AUTOSAR XML (schema 00044)
package /E40_Platform_System_SystemPackage/Components
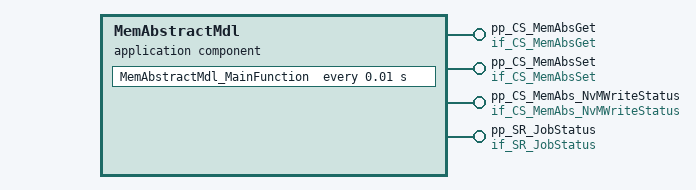
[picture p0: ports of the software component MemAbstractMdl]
  application sw component type MemAbstractMdl
    4 x provide port:
      pp_CS_MemAbsGet: provided-interface=if_CS_MemAbsGet
        provided-com-specs:
          operation=Get_BsConst_Audio_Element, queue-length=1
          operation=Get_BsConst_Communication_Element, queue-length=1
          operation=Get_BsConst_EngOffTimer_Element, queue-length=1
          operation=Get_BsConst_FuelGauge_Element, queue-length=1
          operation=Get_BsConst_Illumination_Element, queue-length=1
          operation=Get_BsConst_OilGauge_Element, queue-length=1
          operation=Get_BsConst_PowerGauge_Element, queue-length=1
          operation=Get_BsConst_Power_Element, queue-length=1
          operation=Get_BsConst_RealTimeClock_Element, queue-length=1
          operation=Get_BsConst_ServiceReminder_Element, queue-length=1
          operation=Get_BsConst_SpeedoGauge_Element, queue-length=1
          operation=Get_BsConst_TachoGauge_Element, queue-length=1
          operation=Get_BsConst_TempGauge_Element, queue-length=1
          operation=Get_BsConst_TripComputer_Element, queue-length=1
          operation=Get_BsConst_Warning_Element, queue-length=1
          operation=Get_BsCys_Certicificate_Element, queue-length=1
          operation=Get_BsDiag_Dtc_Element, queue-length=1
          operation=Get_BsDiag_ErrorRecord_Element, queue-length=1
          operation=Get_BsFuSa_Audio_Element, queue-length=1
          operation=Get_BsFuSa_Communication_Element, queue-length=1
          operation=Get_BsFuSa_Config_Element, queue-length=1
          operation=Get_BsFuSa_Display_Element, queue-length=1
          operation=Get_BsFuSa_Power_Element, queue-length=1
          operation=Get_BsFuSa_Warning_Element, queue-length=1
          operation=Get_BsFusa_Fota_Element, queue-length=1
          operation=Get_BsReten_Audio_Element, queue-length=1
          operation=Get_BsReten_Communication_Element, queue-length=1
          operation=Get_BsReten_Display_Element, queue-length=1
          operation=Get_BsReten_Gauges_Element, queue-length=1
          operation=Get_BsReten_Illumination_Element, queue-length=1
          operation=Get_BsReten_Odometer_Element, queue-length=1
          operation=Get_BsReten_Personalization_Element, queue-length=1
          operation=Get_BsReten_Power_Element, queue-length=1
          operation=Get_BsReten_RealTimeClock_Element, queue-length=1
          operation=Get_BsReten_Tripcomputer_Element, queue-length=1
          operation=Get_BsReten_VisDlt_Element, queue-length=1
          operation=Get_BsReten_Warning_Element, queue-length=1
          operation=Get_BsRt_CusDlt_Element, queue-length=1
          operation=Get_BsRt_FuelGauge_Element, queue-length=1
          operation=Get_BsRt_Illumination_Element, queue-length=1
          operation=Get_BsRt_Odometer_Element, queue-length=1
          operation=Get_BsRt_OilGauge_Element, queue-length=1
          operation=Get_BsRt_Personalization_Element, queue-length=1
          operation=Get_BsRt_PowerGauge_Element, queue-length=1
          operation=Get_BsRt_RealTimeClock_Element, queue-length=1
          operation=Get_BsRt_SpeedoGauge_Element, queue-length=1
          operation=Get_BsRt_TachoGauge_Element, queue-length=1
          operation=Get_BsRt_TempGauge_Element, queue-length=1
          operation=Get_BsRt_TripComputer_Element, queue-length=1
          operation=Get_BsRt_Warning_Element, queue-length=1
          operation=Get_BsShare_EcuPartNumber_Element, queue-length=1
          operation=Get_BsShare_SwUpdFotaFinPrint_Element, queue-length=1
          operation=Get_BsShare_SwUpdFotaMode_Element, queue-length=1
          operation=Get_BsShare_SwUpdFotaStatus_Element, queue-length=1
          operation=Get_BsShare_SwUpdFotadecrypt_Element, queue-length=1
          operation=Get_BsShare_SwUpdReflash_Element, queue-length=1
          operation=Get_BsShare_VehicleConfig_Element, queue-length=1
          operation=Get_BsShare_VisMeet_Element, queue-length=1
          operation=Get_RefCys_Certicificate1_Element, queue-length=1
          operation=Get_RefCys_Certicificate_Element, queue-length=1
      pp_CS_MemAbsSet: provided-interface=if_CS_MemAbsSet
        provided-com-specs:
          operation=Set_BsConst_Audio_Element, queue-length=1
          operation=Set_BsConst_Communication_Element, queue-length=1
          operation=Set_BsConst_EngOffTimer_Element, queue-length=1
          operation=Set_BsConst_FuelGauge_Element, queue-length=1
          operation=Set_BsConst_Illumination_Element, queue-length=1
          operation=Set_BsConst_OilGauge_Element, queue-length=1
          operation=Set_BsConst_PowerGauge_Element, queue-length=1
          operation=Set_BsConst_Power_Element, queue-length=1
          operation=Set_BsConst_RealTimeClock_Element, queue-length=1
          operation=Set_BsConst_ServiceReminder_Element, queue-length=1
          operation=Set_BsConst_SpeedoGauge_Element, queue-length=1
          operation=Set_BsConst_TachoGauge_Element, queue-length=1
          operation=Set_BsConst_TempGauge_Element, queue-length=1
          operation=Set_BsConst_TripComputer_Element, queue-length=1
          operation=Set_BsConst_Warning_Element, queue-length=1
          operation=Set_BsCys_Certicificate_Element, queue-length=1
          operation=Set_BsDiag_Dtc_Element, queue-length=1
          operation=Set_BsDiag_ErrorRecord_Element, queue-length=1
          operation=Set_BsFuSa_Audio_Element, queue-length=1
          operation=Set_BsFuSa_Communication_Element, queue-length=1
          operation=Set_BsFuSa_Config_Element, queue-length=1
          operation=Set_BsFuSa_Display_Element, queue-length=1
          operation=Set_BsFuSa_Power_Element, queue-length=1
          operation=Set_BsFuSa_Warning_Element, queue-length=1
          operation=Set_BsFusa_Fota_Element, queue-length=1
          operation=Set_BsReten_Audio_Element, queue-length=1
          operation=Set_BsReten_Communication_Element, queue-length=1
          operation=Set_BsReten_Display_Element, queue-length=1
          operation=Set_BsReten_Gauges_Element, queue-length=1
          operation=Set_BsReten_Illumination_Element, queue-length=1
          operation=Set_BsReten_Odometer_Element, queue-length=1
          operation=Set_BsReten_Personalization_Element, queue-length=1
          operation=Set_BsReten_Power_Element, queue-length=1
          operation=Set_BsReten_RealTimeClock_Element, queue-length=1
          operation=Set_BsReten_Tripcomputer_Element, queue-length=1
          operation=Set_BsReten_VisDlt_Element, queue-length=1
          operation=Set_BsReten_Warning_Element, queue-length=1
          operation=Set_BsRt_CusDlt_Element, queue-length=1
          operation=Set_BsRt_FuelGauge_Element, queue-length=1
          operation=Set_BsRt_Illumination_Element, queue-length=1
          operation=Set_BsRt_Odometer_Element, queue-length=1
          operation=Set_BsRt_OilGauge_Element, queue-length=1
          operation=Set_BsRt_Personalization_Element, queue-length=1
          operation=Set_BsRt_PowerGauge_Element, queue-length=1
          operation=Set_BsRt_RealTimeClock_Element, queue-length=1
          operation=Set_BsRt_SpeedoGauge_Element, queue-length=1
          operation=Set_BsRt_TachoGauge_Element, queue-length=1
          operation=Set_BsRt_TempGauge_Element, queue-length=1
          operation=Set_BsRt_TripComputer_Element, queue-length=1
          operation=Set_BsRt_Warning_Element, queue-length=1
          operation=Set_BsShare_EcuPartNumber_Element, queue-length=1
          operation=Set_BsShare_SwUpdFotaFinPrint_Element, queue-length=1
          operation=Set_BsShare_SwUpdFotaMode_Element, queue-length=1
          operation=Set_BsShare_SwUpdFotaStatus_Element, queue-length=1
          operation=Set_BsShare_SwUpdFotadecrypt_Element, queue-length=1
          operation=Set_BsShare_SwUpdReflash_Element, queue-length=1
          operation=Set_BsShare_VehicleConfig_Element, queue-length=1
          operation=Set_BsShare_VisMeet_Element, queue-length=1
          operation=Set_RefCys_Certicificate1_Element, queue-length=1
          operation=Set_RefCys_Certicificate_Element, queue-length=1
      pp_CS_MemAbs_NvMWriteStatus: server-com-spec{operation=NvmWriteStatus, queue-length=1}, provided-interface=if_CS_MemAbs_NvMWriteStatus
      pp_SR_JobStatus: provided-interface=if_SR_JobStatus
        provided-com-specs:
          data-element=JobStatus_BsConst_Audio_Element, init-value=constant-reference=MemAbstractMdlJobStatus_BsConst_Audio_ElementValue0
          data-element=JobStatus_BsConst_Communication_Element, init-value=constant-reference=MemAbstractMdlJobStatus_BsConst_Communication_ElementValue0
          data-element=JobStatus_BsConst_EngOffTimer_Element, init-value=constant-reference=MemAbstractMdlJobStatus_BsConst_EngOffTimer_ElementValue0
          data-element=JobStatus_BsConst_FuelGauge_Element, init-value=constant-reference=MemAbstractMdlJobStatus_BsConst_FuelGauge_ElementValue0
          data-element=JobStatus_BsConst_Illumination_Element, init-value=constant-reference=MemAbstractMdlJobStatus_BsConst_Illumination_ElementValue0
          data-element=JobStatus_BsConst_OilGauge_Element, init-value=constant-reference=MemAbstractMdlJobStatus_BsConst_OilGauge_ElementValue0
          data-element=JobStatus_BsConst_PowerGauge_Element, init-value=constant-reference=MemAbstractMdlJobStatus_BsConst_PowerGauge_ElementValue0
          data-element=JobStatus_BsConst_Power_Element, init-value=constant-reference=MemAbstractMdlJobStatus_BsConst_Power_ElementValue0
          data-element=JobStatus_BsConst_RealTimeClock_Element, init-value=constant-reference=MemAbstractMdlJobStatus_BsConst_RealTimeClock_ElementValue0
          data-element=JobStatus_BsConst_ServiceReminder_Element, init-value=constant-reference=MemAbstractMdlJobStatus_BsConst_ServiceReminder_ElementValue0
          data-element=JobStatus_BsConst_SpeedoGauge_Element, init-value=constant-reference=MemAbstractMdlJobStatus_BsConst_SpeedoGauge_ElementValue0
          data-element=JobStatus_BsConst_TachoGauge_Element, init-value=constant-reference=MemAbstractMdlJobStatus_BsConst_TachoGauge_ElementValue0
          data-element=JobStatus_BsConst_TempGauge_Element, init-value=constant-reference=MemAbstractMdlJobStatus_BsConst_TempGauge_ElementValue0
          data-element=JobStatus_BsConst_TripComputer_Element, init-value=constant-reference=MemAbstractMdlJobStatus_BsConst_TripComputer_ElementValue0
          data-element=JobStatus_BsConst_Warning_Element, init-value=constant-reference=MemAbstractMdlJobStatus_BsConst_Warning_ElementValue0
          data-element=JobStatus_BsCys_Certicificate_Element, init-value=constant-reference=MemAbstractMdlJobStatus_BsCys_Certicificate_ElementValue0
          data-element=JobStatus_BsDiag_Dtc_Element, init-value=constant-reference=MemAbstractMdlJobStatus_BsDiag_Dtc_ElementValue0
          data-element=JobStatus_BsDiag_ErrorRecord_Element, init-value=constant-reference=MemAbstractMdlJobStatus_BsDiag_ErrorRecord_ElementValue0
          data-element=JobStatus_BsFuSa_Audio_Element, init-value=constant-reference=MemAbstractMdlJobStatus_BsFuSa_Audio_ElementValue0
          data-element=JobStatus_BsFuSa_Communication_Element, init-value=constant-reference=MemAbstractMdlJobStatus_BsFuSa_Communication_ElementValue0
          data-element=JobStatus_BsFuSa_Config_Element, init-value=constant-reference=MemAbstractMdlJobStatus_BsFuSa_Config_ElementValue0
          data-element=JobStatus_BsFuSa_Display_Element, init-value=constant-reference=MemAbstractMdlJobStatus_BsFuSa_Display_ElementValue0
          data-element=JobStatus_BsFuSa_Power_Element, init-value=constant-reference=MemAbstractMdlJobStatus_BsFuSa_Power_ElementValue0
          data-element=JobStatus_BsFuSa_Warning_Element, init-value=constant-reference=MemAbstractMdlJobStatus_BsFuSa_Warning_ElementValue0
          data-element=JobStatus_BsFusa_Fota_Element, init-value=constant-reference=MemAbstractMdlJobStatus_BsFusa_Fota_ElementValue0
          data-element=JobStatus_BsReten_Audio_Element, init-value=constant-reference=MemAbstractMdlJobStatus_BsReten_Audio_ElementValue0
          data-element=JobStatus_BsReten_Communication_Element, init-value=constant-reference=MemAbstractMdlJobStatus_BsReten_Communication_ElementValue0
          data-element=JobStatus_BsReten_Display_Element, init-value=constant-reference=MemAbstractMdlJobStatus_BsReten_Display_ElementValue0
          data-element=JobStatus_BsReten_Gauges_Element, init-value=constant-reference=MemAbstractMdlJobStatus_BsReten_Gauges_ElementValue0
          data-element=JobStatus_BsReten_Illumination_Element, init-value=constant-reference=MemAbstractMdlJobStatus_BsReten_Illumination_ElementValue0
          data-element=JobStatus_BsReten_Odometer_Element, init-value=constant-reference=MemAbstractMdlJobStatus_BsReten_Odometer_ElementValue0
          data-element=JobStatus_BsReten_Personalization_Element, init-value=constant-reference=MemAbstractMdlJobStatus_BsReten_Personalization_ElementValue0
          data-element=JobStatus_BsReten_Power_Element, init-value=constant-reference=MemAbstractMdlJobStatus_BsReten_Power_ElementValue0
          data-element=JobStatus_BsReten_RealTimeClock_Element, init-value=constant-reference=MemAbstractMdlJobStatus_BsReten_RealTimeClock_ElementValue0
          data-element=JobStatus_BsReten_Tripcomputer_Element, init-value=constant-reference=MemAbstractMdlJobStatus_BsReten_Tripcomputer_ElementValue0
          data-element=JobStatus_BsReten_VisDlt_Element, init-value=constant-reference=MemAbstractMdlJobStatus_BsReten_VisDlt_ElementValue0
          data-element=JobStatus_BsReten_Warning_Element, init-value=constant-reference=MemAbstractMdlJobStatus_BsReten_Warning_ElementValue0
          data-element=JobStatus_BsRt_CusDlt_Element, init-value=constant-reference=MemAbstractMdlJobStatus_BsRt_CusDlt_ElementValue0
          data-element=JobStatus_BsRt_FuelGauge_Element, init-value=constant-reference=MemAbstractMdlJobStatus_BsRt_FuelGauge_ElementValue0
          data-element=JobStatus_BsRt_Illumination_Element, init-value=constant-reference=MemAbstractMdlJobStatus_BsRt_Illumination_ElementValue0
          data-element=JobStatus_BsRt_Odometer_Element, init-value=constant-reference=MemAbstractMdlJobStatus_BsRt_Odometer_ElementValue0
          data-element=JobStatus_BsRt_OilGauge_Element, init-value=constant-reference=MemAbstractMdlJobStatus_BsRt_OilGauge_ElementValue0
          data-element=JobStatus_BsRt_Personalization_Element, init-value=constant-reference=MemAbstractMdlJobStatus_BsRt_Personalization_ElementValue0
          data-element=JobStatus_BsRt_PowerGauge_Element, init-value=constant-reference=MemAbstractMdlJobStatus_BsRt_PowerGauge_ElementValue0
          data-element=JobStatus_BsRt_RealTimeClock_Element, init-value=constant-reference=MemAbstractMdlJobStatus_BsRt_RealTimeClock_ElementValue0
          data-element=JobStatus_BsRt_SpeedoGauge_Element, init-value=constant-reference=MemAbstractMdlJobStatus_BsRt_SpeedoGauge_ElementValue0
          data-element=JobStatus_BsRt_TachoGauge_Element, init-value=constant-reference=MemAbstractMdlJobStatus_BsRt_TachoGauge_ElementValue0
          data-element=JobStatus_BsRt_TempGauge_Element, init-value=constant-reference=MemAbstractMdlJobStatus_BsRt_TempGauge_ElementValue0
          data-element=JobStatus_BsRt_TripComputer_Element, init-value=constant-reference=MemAbstractMdlJobStatus_BsRt_TripComputer_ElementValue0
          data-element=JobStatus_BsRt_Warning_Element, init-value=constant-reference=MemAbstractMdlJobStatus_BsRt_Warning_ElementValue0
          data-element=JobStatus_BsShare_EcuPartNumber_Element, init-value=constant-reference=MemAbstractMdlJobStatus_BsShare_EcuPartNumber_ElementValue0
          data-element=JobStatus_BsShare_SwUpdFotaFinPrint_Element, init-value=constant-reference=MemAbstractMdlJobStatus_BsShare_SwUpdFotaFinPrint_ElementValue0
          data-element=JobStatus_BsShare_SwUpdFotaMode_Element, init-value=constant-reference=MemAbstractMdlJobStatus_BsShare_SwUpdFotaMode_ElementValue0
          data-element=JobStatus_BsShare_SwUpdFotaStatus_Element, init-value=constant-reference=MemAbstractMdlJobStatus_BsShare_SwUpdFotaStatus_ElementValue0
          data-element=JobStatus_BsShare_SwUpdFotadecrypt_Element, init-value=constant-reference=MemAbstractMdlJobStatus_BsShare_SwUpdFotadecrypt_ElementValue0
          data-element=JobStatus_BsShare_SwUpdReflash_Element, init-value=constant-reference=MemAbstractMdlJobStatus_BsShare_SwUpdReflash_ElementValue0
          data-element=JobStatus_BsShare_VehicleConfig_Element, init-value=constant-reference=MemAbstractMdlJobStatus_BsShare_VehicleConfig_ElementValue0
          data-element=JobStatus_BsShare_VisMeet_Element, init-value=constant-reference=MemAbstractMdlJobStatus_BsShare_VisMeet_ElementValue0
          data-element=JobStatus_RefCys_Certicificate1_Element, init-value=constant-reference=MemAbstractMdlJobStatus_RefCys_Certicificate1_ElementValue0
          data-element=JobStatus_RefCys_Certicificate_Element, init-value=constant-reference=MemAbstractMdlJobStatus_RefCys_Certicificate_ElementValue0
    behavior IB_MemAbstractMdl
      121 x operation invoked event:
        OIE_pp_CS_MemAbs_NvMWriteStatus_MemAbstractMdl_NvmWriteStatusTrigByNvmWriteStatus: start-on-event=MemAbstractMdl_NvmWriteStatus, operation=pp_CS_MemAbs_NvMWriteStatus.NvmWriteStatus
        OIE_pp_CS_MemAbsGet_MemAbstractMdl_Get_BsConst_Audio_ElementTrigByGet_BsConst_Audio_Element: start-on-event=MemAbstractMdl_Get_BsConst_Audio_Element, operation=pp_CS_MemAbsGet.Get_BsConst_Audio_Element
        OIE_pp_CS_MemAbsGet_MemAbstractMdl_Get_BsConst_Communication_ElementTrigByGet_BsConst_Communication_Element: start-on-event=MemAbstractMdl_Get_BsConst_Communication_Element, operation=pp_CS_MemAbsGet.Get_BsConst_Communication_Element
        OIE_pp_CS_MemAbsGet_MemAbstractMdl_Get_BsConst_EngOffTimer_ElementTrigByGet_BsConst_EngOffTimer_Element: start-on-event=MemAbstractMdl_Get_BsConst_EngOffTimer_Element, operation=pp_CS_MemAbsGet.Get_BsConst_EngOffTimer_Element
        OIE_pp_CS_MemAbsGet_MemAbstractMdl_Get_BsConst_FuelGauge_ElementTrigByGet_BsConst_FuelGauge_Element: start-on-event=MemAbstractMdl_Get_BsConst_FuelGauge_Element, operation=pp_CS_MemAbsGet.Get_BsConst_FuelGauge_Element
        OIE_pp_CS_MemAbsGet_MemAbstractMdl_Get_BsConst_Illumination_ElementTrigByGet_BsConst_Illumination_Element: start-on-event=MemAbstractMdl_Get_BsConst_Illumination_Element, operation=pp_CS_MemAbsGet.Get_BsConst_Illumination_Element
        OIE_pp_CS_MemAbsGet_MemAbstractMdl_Get_BsConst_OilGauge_ElementTrigByGet_BsConst_OilGauge_Element: start-on-event=MemAbstractMdl_Get_BsConst_OilGauge_Element, operation=pp_CS_MemAbsGet.Get_BsConst_OilGauge_Element
        OIE_pp_CS_MemAbsGet_MemAbstractMdl_Get_BsConst_PowerGauge_ElementTrigByGet_BsConst_PowerGauge_Element: start-on-event=MemAbstractMdl_Get_BsConst_PowerGauge_Element, operation=pp_CS_MemAbsGet.Get_BsConst_PowerGauge_Element
        OIE_pp_CS_MemAbsGet_MemAbstractMdl_Get_BsConst_Power_ElementTrigByGet_BsConst_Power_Element: start-on-event=MemAbstractMdl_Get_BsConst_Power_Element, operation=pp_CS_MemAbsGet.Get_BsConst_Power_Element
        OIE_pp_CS_MemAbsGet_MemAbstractMdl_Get_BsConst_RealTimeClock_ElementTrigByGet_BsConst_RealTimeClock_Element: start-on-event=MemAbstractMdl_Get_BsConst_RealTimeClock_Element, operation=pp_CS_MemAbsGet.Get_BsConst_RealTimeClock_Element
        OIE_pp_CS_MemAbsGet_MemAbstractMdl_Get_BsConst_ServiceReminder_ElementTrigByGet_BsConst_ServiceReminder_Element: start-on-event=MemAbstractMdl_Get_BsConst_ServiceReminder_Element, operation=pp_CS_MemAbsGet.Get_BsConst_ServiceReminder_Element
        OIE_pp_CS_MemAbsGet_MemAbstractMdl_Get_BsConst_SpeedoGauge_ElementTrigByGet_BsConst_SpeedoGauge_Element: start-on-event=MemAbstractMdl_Get_BsConst_SpeedoGauge_Element, operation=pp_CS_MemAbsGet.Get_BsConst_SpeedoGauge_Element
        OIE_pp_CS_MemAbsGet_MemAbstractMdl_Get_BsConst_TachoGauge_ElementTrigByGet_BsConst_TachoGauge_Element: start-on-event=MemAbstractMdl_Get_BsConst_TachoGauge_Element, operation=pp_CS_MemAbsGet.Get_BsConst_TachoGauge_Element
        OIE_pp_CS_MemAbsGet_MemAbstractMdl_Get_BsConst_TempGauge_ElementTrigByGet_BsConst_TempGauge_Element: start-on-event=MemAbstractMdl_Get_BsConst_TempGauge_Element, operation=pp_CS_MemAbsGet.Get_BsConst_TempGauge_Element
        OIE_pp_CS_MemAbsGet_MemAbstractMdl_Get_BsConst_TripComputer_ElementTrigByGet_BsConst_TripComputer_Element: start-on-event=MemAbstractMdl_Get_BsConst_TripComputer_Element, operation=pp_CS_MemAbsGet.Get_BsConst_TripComputer_Element
        OIE_pp_CS_MemAbsGet_MemAbstractMdl_Get_BsConst_Warning_ElementTrigByGet_BsConst_Warning_Element: start-on-event=MemAbstractMdl_Get_BsConst_Warning_Element, operation=pp_CS_MemAbsGet.Get_BsConst_Warning_Element
        OIE_pp_CS_MemAbsGet_MemAbstractMdl_Get_BsCys_Certicificate_ElementTrigByGet_BsCys_Certicificate_Element: start-on-event=MemAbstractMdl_Get_BsCys_Certicificate_Element, operation=pp_CS_MemAbsGet.Get_BsCys_Certicificate_Element
        OIE_pp_CS_MemAbsGet_MemAbstractMdl_Get_BsDiag_Dtc_ElementTrigByGet_BsDiag_Dtc_Element: start-on-event=MemAbstractMdl_Get_BsDiag_Dtc_Element, operation=pp_CS_MemAbsGet.Get_BsDiag_Dtc_Element
        OIE_pp_CS_MemAbsGet_MemAbstractMdl_Get_BsDiag_ErrorRecord_ElementTrigByGet_BsDiag_ErrorRecord_Element: start-on-event=MemAbstractMdl_Get_BsDiag_ErrorRecord_Element, operation=pp_CS_MemAbsGet.Get_BsDiag_ErrorRecord_Element
        OIE_pp_CS_MemAbsGet_MemAbstractMdl_Get_BsFuSa_Audio_ElementTrigByGet_BsFuSa_Audio_Element: start-on-event=MemAbstractMdl_Get_BsFuSa_Audio_Element, operation=pp_CS_MemAbsGet.Get_BsFuSa_Audio_Element
        OIE_pp_CS_MemAbsGet_MemAbstractMdl_Get_BsFuSa_Communication_ElementTrigByGet_BsFuSa_Communication_Element: start-on-event=MemAbstractMdl_Get_BsFuSa_Communication_Element, operation=pp_CS_MemAbsGet.Get_BsFuSa_Communication_Element
        OIE_pp_CS_MemAbsGet_MemAbstractMdl_Get_BsFuSa_Config_ElementTrigByGet_BsFuSa_Config_Element: start-on-event=MemAbstractMdl_Get_BsFuSa_Config_Element, operation=pp_CS_MemAbsGet.Get_BsFuSa_Config_Element
        OIE_pp_CS_MemAbsGet_MemAbstractMdl_Get_BsFuSa_Display_ElementTrigByGet_BsFuSa_Display_Element: start-on-event=MemAbstractMdl_Get_BsFuSa_Display_Element, operation=pp_CS_MemAbsGet.Get_BsFuSa_Display_Element
        OIE_pp_CS_MemAbsGet_MemAbstractMdl_Get_BsFuSa_Power_ElementTrigByGet_BsFuSa_Power_Element: start-on-event=MemAbstractMdl_Get_BsFuSa_Power_Element, operation=pp_CS_MemAbsGet.Get_BsFuSa_Power_Element
        OIE_pp_CS_MemAbsGet_MemAbstractMdl_Get_BsFuSa_Warning_ElementTrigByGet_BsFuSa_Warning_Element: start-on-event=MemAbstractMdl_Get_BsFuSa_Warning_Element, operation=pp_CS_MemAbsGet.Get_BsFuSa_Warning_Element
        OIE_pp_CS_MemAbsGet_MemAbstractMdl_Get_BsFusa_Fota_ElementTrigByGet_BsFusa_Fota_Element: start-on-event=MemAbstractMdl_Get_BsFusa_Fota_Element, operation=pp_CS_MemAbsGet.Get_BsFusa_Fota_Element
        OIE_pp_CS_MemAbsGet_MemAbstractMdl_Get_BsReten_Audio_ElementTrigByGet_BsReten_Audio_Element: start-on-event=MemAbstractMdl_Get_BsReten_Audio_Element, operation=pp_CS_MemAbsGet.Get_BsReten_Audio_Element
        OIE_pp_CS_MemAbsGet_MemAbstractMdl_Get_BsReten_Communication_ElementTrigByGet_BsReten_Communication_Element: start-on-event=MemAbstractMdl_Get_BsReten_Communication_Element, operation=pp_CS_MemAbsGet.Get_BsReten_Communication_Element
        OIE_pp_CS_MemAbsGet_MemAbstractMdl_Get_BsReten_Display_ElementTrigByGet_BsReten_Display_Element: start-on-event=MemAbstractMdl_Get_BsReten_Display_Element, operation=pp_CS_MemAbsGet.Get_BsReten_Display_Element
        OIE_pp_CS_MemAbsGet_MemAbstractMdl_Get_BsReten_Gauges_ElementTrigByGet_BsReten_Gauges_Element: start-on-event=MemAbstractMdl_Get_BsReten_Gauges_Element, operation=pp_CS_MemAbsGet.Get_BsReten_Gauges_Element
        OIE_pp_CS_MemAbsGet_MemAbstractMdl_Get_BsReten_Illumination_ElementTrigByGet_BsReten_Illumination_Element: start-on-event=MemAbstractMdl_Get_BsReten_Illumination_Element, operation=pp_CS_MemAbsGet.Get_BsReten_Illumination_Element
        OIE_pp_CS_MemAbsGet_MemAbstractMdl_Get_BsReten_Odometer_ElementTrigByGet_BsReten_Odometer_Element: start-on-event=MemAbstractMdl_Get_BsReten_Odometer_Element, operation=pp_CS_MemAbsGet.Get_BsReten_Odometer_Element
        OIE_pp_CS_MemAbsGet_MemAbstractMdl_Get_BsReten_Personalization_ElementTrigByGet_BsReten_Personalization_Element: start-on-event=MemAbstractMdl_Get_BsReten_Personalization_Element, operation=pp_CS_MemAbsGet.Get_BsReten_Personalization_Element
        OIE_pp_CS_MemAbsGet_MemAbstractMdl_Get_BsReten_Power_ElementTrigByGet_BsReten_Power_Element: start-on-event=MemAbstractMdl_Get_BsReten_Power_Element, operation=pp_CS_MemAbsGet.Get_BsReten_Power_Element
        OIE_pp_CS_MemAbsGet_MemAbstractMdl_Get_BsReten_RealTimeClock_ElementTrigByGet_BsReten_RealTimeClock_Element: start-on-event=MemAbstractMdl_Get_BsReten_RealTimeClock_Element, operation=pp_CS_MemAbsGet.Get_BsReten_RealTimeClock_Element
        OIE_pp_CS_MemAbsGet_MemAbstractMdl_Get_BsReten_Tripcomputer_ElementTrigByGet_BsReten_Tripcomputer_Element: start-on-event=MemAbstractMdl_Get_BsReten_Tripcomputer_Element, operation=pp_CS_MemAbsGet.Get_BsReten_Tripcomputer_Element
        OIE_pp_CS_MemAbsGet_MemAbstractMdl_Get_BsReten_VisDlt_ElementTrigByGet_BsReten_VisDlt_Element: start-on-event=MemAbstractMdl_Get_BsReten_VisDlt_Element, operation=pp_CS_MemAbsGet.Get_BsReten_VisDlt_Element
        OIE_pp_CS_MemAbsGet_MemAbstractMdl_Get_BsReten_Warning_ElementTrigByGet_BsReten_Warning_Element: start-on-event=MemAbstractMdl_Get_BsReten_Warning_Element, operation=pp_CS_MemAbsGet.Get_BsReten_Warning_Element
        OIE_pp_CS_MemAbsGet_MemAbstractMdl_Get_BsRt_CusDlt_ElementTrigByGet_BsRt_CusDlt_Element: start-on-event=MemAbstractMdl_Get_BsRt_CusDlt_Element, operation=pp_CS_MemAbsGet.Get_BsRt_CusDlt_Element
        OIE_pp_CS_MemAbsGet_MemAbstractMdl_Get_BsRt_FuelGauge_ElementTrigByGet_BsRt_FuelGauge_Element: start-on-event=MemAbstractMdl_Get_BsRt_FuelGauge_Element, operation=pp_CS_MemAbsGet.Get_BsRt_FuelGauge_Element
        OIE_pp_CS_MemAbsGet_MemAbstractMdl_Get_BsRt_Illumination_ElementTrigByGet_BsRt_Illumination_Element: start-on-event=MemAbstractMdl_Get_BsRt_Illumination_Element, operation=pp_CS_MemAbsGet.Get_BsRt_Illumination_Element
        OIE_pp_CS_MemAbsGet_MemAbstractMdl_Get_BsRt_Odometer_ElementTrigByGet_BsRt_Odometer_Element: start-on-event=MemAbstractMdl_Get_BsRt_Odometer_Element, operation=pp_CS_MemAbsGet.Get_BsRt_Odometer_Element
        OIE_pp_CS_MemAbsGet_MemAbstractMdl_Get_BsRt_OilGauge_ElementTrigByGet_BsRt_OilGauge_Element: start-on-event=MemAbstractMdl_Get_BsRt_OilGauge_Element, operation=pp_CS_MemAbsGet.Get_BsRt_OilGauge_Element
        OIE_pp_CS_MemAbsGet_MemAbstractMdl_Get_BsRt_Personalization_ElementTrigByGet_BsRt_Personalization_Element: start-on-event=MemAbstractMdl_Get_BsRt_Personalization_Element, operation=pp_CS_MemAbsGet.Get_BsRt_Personalization_Element
        OIE_pp_CS_MemAbsGet_MemAbstractMdl_Get_BsRt_PowerGauge_ElementTrigByGet_BsRt_PowerGauge_Element: start-on-event=MemAbstractMdl_Get_BsRt_PowerGauge_Element, operation=pp_CS_MemAbsGet.Get_BsRt_PowerGauge_Element
        OIE_pp_CS_MemAbsGet_MemAbstractMdl_Get_BsRt_RealTimeClock_ElementTrigByGet_BsRt_RealTimeClock_Element: start-on-event=MemAbstractMdl_Get_BsRt_RealTimeClock_Element, operation=pp_CS_MemAbsGet.Get_BsRt_RealTimeClock_Element
        OIE_pp_CS_MemAbsGet_MemAbstractMdl_Get_BsRt_SpeedoGauge_ElementTrigByGet_BsRt_SpeedoGauge_Element: start-on-event=MemAbstractMdl_Get_BsRt_SpeedoGauge_Element, operation=pp_CS_MemAbsGet.Get_BsRt_SpeedoGauge_Element
        OIE_pp_CS_MemAbsGet_MemAbstractMdl_Get_BsRt_TachoGauge_ElementTrigByGet_BsRt_TachoGauge_Element: start-on-event=MemAbstractMdl_Get_BsRt_TachoGauge_Element, operation=pp_CS_MemAbsGet.Get_BsRt_TachoGauge_Element
        OIE_pp_CS_MemAbsGet_MemAbstractMdl_Get_BsRt_TempGauge_ElementTrigByGet_BsRt_TempGauge_Element: start-on-event=MemAbstractMdl_Get_BsRt_TempGauge_Element, operation=pp_CS_MemAbsGet.Get_BsRt_TempGauge_Element
        OIE_pp_CS_MemAbsGet_MemAbstractMdl_Get_BsRt_TripComputer_ElementTrigByGet_BsRt_TripComputer_Element: start-on-event=MemAbstractMdl_Get_BsRt_TripComputer_Element, operation=pp_CS_MemAbsGet.Get_BsRt_TripComputer_Element
        OIE_pp_CS_MemAbsGet_MemAbstractMdl_Get_BsRt_Warning_ElementTrigByGet_BsRt_Warning_Element: start-on-event=MemAbstractMdl_Get_BsRt_Warning_Element, operation=pp_CS_MemAbsGet.Get_BsRt_Warning_Element
        OIE_pp_CS_MemAbsGet_MemAbstractMdl_Get_BsShare_EcuPartNumber_ElementTrigByGet_BsShare_EcuPartNumber_Element: start-on-event=MemAbstractMdl_Get_BsShare_EcuPartNumber_Element, operation=pp_CS_MemAbsGet.Get_BsShare_EcuPartNumber_Element
        OIE_pp_CS_MemAbsGet_MemAbstractMdl_Get_BsShare_SwUpdFotaFinPrint_ElementTrigByGet_BsShare_SwUpdFotaFinPrint_Element: start-on-event=MemAbstractMdl_Get_BsShare_SwUpdFotaFinPrint_Element, operation=pp_CS_MemAbsGet.Get_BsShare_SwUpdFotaFinPrint_Element
        OIE_pp_CS_MemAbsGet_MemAbstractMdl_Get_BsShare_SwUpdFotaMode_ElementTrigByGet_BsShare_SwUpdFotaMode_Element: start-on-event=MemAbstractMdl_Get_BsShare_SwUpdFotaMode_Element, operation=pp_CS_MemAbsGet.Get_BsShare_SwUpdFotaMode_Element
        OIE_pp_CS_MemAbsGet_MemAbstractMdl_Get_BsShare_SwUpdFotaStatus_ElementTrigByGet_BsShare_SwUpdFotaStatus_Element: start-on-event=MemAbstractMdl_Get_BsShare_SwUpdFotaStatus_Element, operation=pp_CS_MemAbsGet.Get_BsShare_SwUpdFotaStatus_Element
        OIE_pp_CS_MemAbsGet_MemAbstractMdl_Get_BsShare_SwUpdFotadecrypt_ElementTrigByGet_BsShare_SwUpdFotadecrypt_Element: start-on-event=MemAbstractMdl_Get_BsShare_SwUpdFotadecrypt_Element, operation=pp_CS_MemAbsGet.Get_BsShare_SwUpdFotadecrypt_Element
        OIE_pp_CS_MemAbsGet_MemAbstractMdl_Get_BsShare_SwUpdReflash_ElementTrigByGet_BsShare_SwUpdReflash_Element: start-on-event=MemAbstractMdl_Get_BsShare_SwUpdReflash_Element, operation=pp_CS_MemAbsGet.Get_BsShare_SwUpdReflash_Element
        OIE_pp_CS_MemAbsGet_MemAbstractMdl_Get_BsShare_VehicleConfig_ElementTrigByGet_BsShare_VehicleConfig_Element: start-on-event=MemAbstractMdl_Get_BsShare_VehicleConfig_Element, operation=pp_CS_MemAbsGet.Get_BsShare_VehicleConfig_Element
        OIE_pp_CS_MemAbsGet_MemAbstractMdl_Get_BsShare_VisMeet_ElementTrigByGet_BsShare_VisMeet_Element: start-on-event=MemAbstractMdl_Get_BsShare_VisMeet_Element, operation=pp_CS_MemAbsGet.Get_BsShare_VisMeet_Element
        OIE_pp_CS_MemAbsGet_MemAbstractMdl_Get_RefCys_Certicificate1_ElementTrigByGet_RefCys_Certicificate1_Element: start-on-event=MemAbstractMdl_Get_RefCys_Certicificate1_Element, operation=pp_CS_MemAbsGet.Get_RefCys_Certicificate1_Element
        OIE_pp_CS_MemAbsGet_MemAbstractMdl_Get_RefCys_Certicificate_ElementTrigByGet_RefCys_Certicificate_Element: start-on-event=MemAbstractMdl_Get_RefCys_Certicificate_Element, operation=pp_CS_MemAbsGet.Get_RefCys_Certicificate_Element
        OIE_pp_CS_MemAbsSet_MemAbstractMdl_Set_BsConst_Audio_ElementTrigBySet_BsConst_Audio_Element: start-on-event=MemAbstractMdl_Set_BsConst_Audio_Element, operation=pp_CS_MemAbsSet.Set_BsConst_Audio_Element
        OIE_pp_CS_MemAbsSet_MemAbstractMdl_Set_BsConst_Communication_ElementTrigBySet_BsConst_Communication_Element: start-on-event=MemAbstractMdl_Set_BsConst_Communication_Element, operation=pp_CS_MemAbsSet.Set_BsConst_Communication_Element
        OIE_pp_CS_MemAbsSet_MemAbstractMdl_Set_BsConst_EngOffTimer_ElementTrigBySet_BsConst_EngOffTimer_Element: start-on-event=MemAbstractMdl_Set_BsConst_EngOffTimer_Element, operation=pp_CS_MemAbsSet.Set_BsConst_EngOffTimer_Element
        OIE_pp_CS_MemAbsSet_MemAbstractMdl_Set_BsConst_FuelGauge_ElementTrigBySet_BsConst_FuelGauge_Element: start-on-event=MemAbstractMdl_Set_BsConst_FuelGauge_Element, operation=pp_CS_MemAbsSet.Set_BsConst_FuelGauge_Element
        OIE_pp_CS_MemAbsSet_MemAbstractMdl_Set_BsConst_Illumination_ElementTrigBySet_BsConst_Illumination_Element: start-on-event=MemAbstractMdl_Set_BsConst_Illumination_Element, operation=pp_CS_MemAbsSet.Set_BsConst_Illumination_Element
        OIE_pp_CS_MemAbsSet_MemAbstractMdl_Set_BsConst_OilGauge_ElementTrigBySet_BsConst_OilGauge_Element: start-on-event=MemAbstractMdl_Set_BsConst_OilGauge_Element, operation=pp_CS_MemAbsSet.Set_BsConst_OilGauge_Element
        OIE_pp_CS_MemAbsSet_MemAbstractMdl_Set_BsConst_PowerGauge_ElementTrigBySet_BsConst_PowerGauge_Element: start-on-event=MemAbstractMdl_Set_BsConst_PowerGauge_Element, operation=pp_CS_MemAbsSet.Set_BsConst_PowerGauge_Element
        OIE_pp_CS_MemAbsSet_MemAbstractMdl_Set_BsConst_Power_ElementTrigBySet_BsConst_Power_Element: start-on-event=MemAbstractMdl_Set_BsConst_Power_Element, operation=pp_CS_MemAbsSet.Set_BsConst_Power_Element
        OIE_pp_CS_MemAbsSet_MemAbstractMdl_Set_BsConst_RealTimeClock_ElementTrigBySet_BsConst_RealTimeClock_Element: start-on-event=MemAbstractMdl_Set_BsConst_RealTimeClock_Element, operation=pp_CS_MemAbsSet.Set_BsConst_RealTimeClock_Element
        OIE_pp_CS_MemAbsSet_MemAbstractMdl_Set_BsConst_ServiceReminder_ElementTrigBySet_BsConst_ServiceReminder_Element: start-on-event=MemAbstractMdl_Set_BsConst_ServiceReminder_Element, operation=pp_CS_MemAbsSet.Set_BsConst_ServiceReminder_Element
        OIE_pp_CS_MemAbsSet_MemAbstractMdl_Set_BsConst_SpeedoGauge_ElementTrigBySet_BsConst_SpeedoGauge_Element: start-on-event=MemAbstractMdl_Set_BsConst_SpeedoGauge_Element, operation=pp_CS_MemAbsSet.Set_BsConst_SpeedoGauge_Element
        OIE_pp_CS_MemAbsSet_MemAbstractMdl_Set_BsConst_TachoGauge_ElementTrigBySet_BsConst_TachoGauge_Element: start-on-event=MemAbstractMdl_Set_BsConst_TachoGauge_Element, operation=pp_CS_MemAbsSet.Set_BsConst_TachoGauge_Element
        OIE_pp_CS_MemAbsSet_MemAbstractMdl_Set_BsConst_TempGauge_ElementTrigBySet_BsConst_TempGauge_Element: start-on-event=MemAbstractMdl_Set_BsConst_TempGauge_Element, operation=pp_CS_MemAbsSet.Set_BsConst_TempGauge_Element
        OIE_pp_CS_MemAbsSet_MemAbstractMdl_Set_BsConst_TripComputer_ElementTrigBySet_BsConst_TripComputer_Element: start-on-event=MemAbstractMdl_Set_BsConst_TripComputer_Element, operation=pp_CS_MemAbsSet.Set_BsConst_TripComputer_Element
        OIE_pp_CS_MemAbsSet_MemAbstractMdl_Set_BsConst_Warning_ElementTrigBySet_BsConst_Warning_Element: start-on-event=MemAbstractMdl_Set_BsConst_Warning_Element, operation=pp_CS_MemAbsSet.Set_BsConst_Warning_Element
        OIE_pp_CS_MemAbsSet_MemAbstractMdl_Set_BsCys_Certicificate_ElementTrigBySet_BsCys_Certicificate_Element: start-on-event=MemAbstractMdl_Set_BsCys_Certicificate_Element, operation=pp_CS_MemAbsSet.Set_BsCys_Certicificate_Element
        OIE_pp_CS_MemAbsSet_MemAbstractMdl_Set_BsDiag_Dtc_ElementTrigBySet_BsDiag_Dtc_Element: start-on-event=MemAbstractMdl_Set_BsDiag_Dtc_Element, operation=pp_CS_MemAbsSet.Set_BsDiag_Dtc_Element
        OIE_pp_CS_MemAbsSet_MemAbstractMdl_Set_BsDiag_ErrorRecord_ElementTrigBySet_BsDiag_ErrorRecord_Element: start-on-event=MemAbstractMdl_Set_BsDiag_ErrorRecord_Element, operation=pp_CS_MemAbsSet.Set_BsDiag_ErrorRecord_Element
        OIE_pp_CS_MemAbsSet_MemAbstractMdl_Set_BsFuSa_Audio_ElementTrigBySet_BsFuSa_Audio_Element: start-on-event=MemAbstractMdl_Set_BsFuSa_Audio_Element, operation=pp_CS_MemAbsSet.Set_BsFuSa_Audio_Element
        OIE_pp_CS_MemAbsSet_MemAbstractMdl_Set_BsFuSa_Communication_ElementTrigBySet_BsFuSa_Communication_Element: start-on-event=MemAbstractMdl_Set_BsFuSa_Communication_Element, operation=pp_CS_MemAbsSet.Set_BsFuSa_Communication_Element
        OIE_pp_CS_MemAbsSet_MemAbstractMdl_Set_BsFuSa_Config_ElementTrigBySet_BsFuSa_Config_Element: start-on-event=MemAbstractMdl_Set_BsFuSa_Config_Element, operation=pp_CS_MemAbsSet.Set_BsFuSa_Config_Element
        OIE_pp_CS_MemAbsSet_MemAbstractMdl_Set_BsFuSa_Display_ElementTrigBySet_BsFuSa_Display_Element: start-on-event=MemAbstractMdl_Set_BsFuSa_Display_Element, operation=pp_CS_MemAbsSet.Set_BsFuSa_Display_Element
        OIE_pp_CS_MemAbsSet_MemAbstractMdl_Set_BsFuSa_Power_ElementTrigBySet_BsFuSa_Power_Element: start-on-event=MemAbstractMdl_Set_BsFuSa_Power_Element, operation=pp_CS_MemAbsSet.Set_BsFuSa_Power_Element
        OIE_pp_CS_MemAbsSet_MemAbstractMdl_Set_BsFuSa_Warning_ElementTrigBySet_BsFuSa_Warning_Element: start-on-event=MemAbstractMdl_Set_BsFuSa_Warning_Element, operation=pp_CS_MemAbsSet.Set_BsFuSa_Warning_Element
        OIE_pp_CS_MemAbsSet_MemAbstractMdl_Set_BsFusa_Fota_ElementTrigBySet_BsFusa_Fota_Element: start-on-event=MemAbstractMdl_Set_BsFusa_Fota_Element, operation=pp_CS_MemAbsSet.Set_BsFusa_Fota_Element
        OIE_pp_CS_MemAbsSet_MemAbstractMdl_Set_BsReten_Audio_ElementTrigBySet_BsReten_Audio_Element: start-on-event=MemAbstractMdl_Set_BsReten_Audio_Element, operation=pp_CS_MemAbsSet.Set_BsReten_Audio_Element
        OIE_pp_CS_MemAbsSet_MemAbstractMdl_Set_BsReten_Communication_ElementTrigBySet_BsReten_Communication_Element: start-on-event=MemAbstractMdl_Set_BsReten_Communication_Element, operation=pp_CS_MemAbsSet.Set_BsReten_Communication_Element
        OIE_pp_CS_MemAbsSet_MemAbstractMdl_Set_BsReten_Display_ElementTrigBySet_BsReten_Display_Element: start-on-event=MemAbstractMdl_Set_BsReten_Display_Element, operation=pp_CS_MemAbsSet.Set_BsReten_Display_Element
        OIE_pp_CS_MemAbsSet_MemAbstractMdl_Set_BsReten_Gauges_ElementTrigBySet_BsReten_Gauges_Element: start-on-event=MemAbstractMdl_Set_BsReten_Gauges_Element, operation=pp_CS_MemAbsSet.Set_BsReten_Gauges_Element
        OIE_pp_CS_MemAbsSet_MemAbstractMdl_Set_BsReten_Illumination_ElementTrigBySet_BsReten_Illumination_Element: start-on-event=MemAbstractMdl_Set_BsReten_Illumination_Element, operation=pp_CS_MemAbsSet.Set_BsReten_Illumination_Element
        OIE_pp_CS_MemAbsSet_MemAbstractMdl_Set_BsReten_Odometer_ElementTrigBySet_BsReten_Odometer_Element: start-on-event=MemAbstractMdl_Set_BsReten_Odometer_Element, operation=pp_CS_MemAbsSet.Set_BsReten_Odometer_Element
        OIE_pp_CS_MemAbsSet_MemAbstractMdl_Set_BsReten_Personalization_ElementTrigBySet_BsReten_Personalization_Element: start-on-event=MemAbstractMdl_Set_BsReten_Personalization_Element, operation=pp_CS_MemAbsSet.Set_BsReten_Personalization_Element
        OIE_pp_CS_MemAbsSet_MemAbstractMdl_Set_BsReten_Power_ElementTrigBySet_BsReten_Power_Element: start-on-event=MemAbstractMdl_Set_BsReten_Power_Element, operation=pp_CS_MemAbsSet.Set_BsReten_Power_Element
        OIE_pp_CS_MemAbsSet_MemAbstractMdl_Set_BsReten_RealTimeClock_ElementTrigBySet_BsReten_RealTimeClock_Element: start-on-event=MemAbstractMdl_Set_BsReten_RealTimeClock_Element, operation=pp_CS_MemAbsSet.Set_BsReten_RealTimeClock_Element
        OIE_pp_CS_MemAbsSet_MemAbstractMdl_Set_BsReten_Tripcomputer_ElementTrigBySet_BsReten_Tripcomputer_Element: start-on-event=MemAbstractMdl_Set_BsReten_Tripcomputer_Element, operation=pp_CS_MemAbsSet.Set_BsReten_Tripcomputer_Element
        OIE_pp_CS_MemAbsSet_MemAbstractMdl_Set_BsReten_VisDlt_ElementTrigBySet_BsReten_VisDlt_Element: start-on-event=MemAbstractMdl_Set_BsReten_VisDlt_Element, operation=pp_CS_MemAbsSet.Set_BsReten_VisDlt_Element
        OIE_pp_CS_MemAbsSet_MemAbstractMdl_Set_BsReten_Warning_ElementTrigBySet_BsReten_Warning_Element: start-on-event=MemAbstractMdl_Set_BsReten_Warning_Element, operation=pp_CS_MemAbsSet.Set_BsReten_Warning_Element
        OIE_pp_CS_MemAbsSet_MemAbstractMdl_Set_BsRt_CusDlt_ElementTrigBySet_BsRt_CusDlt_Element: start-on-event=MemAbstractMdl_Set_BsRt_CusDlt_Element, operation=pp_CS_MemAbsSet.Set_BsRt_CusDlt_Element
        OIE_pp_CS_MemAbsSet_MemAbstractMdl_Set_BsRt_FuelGauge_ElementTrigBySet_BsRt_FuelGauge_Element: start-on-event=MemAbstractMdl_Set_BsRt_FuelGauge_Element, operation=pp_CS_MemAbsSet.Set_BsRt_FuelGauge_Element
        OIE_pp_CS_MemAbsSet_MemAbstractMdl_Set_BsRt_Illumination_ElementTrigBySet_BsRt_Illumination_Element: start-on-event=MemAbstractMdl_Set_BsRt_Illumination_Element, operation=pp_CS_MemAbsSet.Set_BsRt_Illumination_Element
        OIE_pp_CS_MemAbsSet_MemAbstractMdl_Set_BsRt_Odometer_ElementTrigBySet_BsRt_Odometer_Element: start-on-event=MemAbstractMdl_Set_BsRt_Odometer_Element, operation=pp_CS_MemAbsSet.Set_BsRt_Odometer_Element
        OIE_pp_CS_MemAbsSet_MemAbstractMdl_Set_BsRt_OilGauge_ElementTrigBySet_BsRt_OilGauge_Element: start-on-event=MemAbstractMdl_Set_BsRt_OilGauge_Element, operation=pp_CS_MemAbsSet.Set_BsRt_OilGauge_Element
        OIE_pp_CS_MemAbsSet_MemAbstractMdl_Set_BsRt_Personalization_ElementTrigBySet_BsRt_Personalization_Element: start-on-event=MemAbstractMdl_Set_BsRt_Personalization_Element, operation=pp_CS_MemAbsSet.Set_BsRt_Personalization_Element
        OIE_pp_CS_MemAbsSet_MemAbstractMdl_Set_BsRt_PowerGauge_ElementTrigBySet_BsRt_PowerGauge_Element: start-on-event=MemAbstractMdl_Set_BsRt_PowerGauge_Element, operation=pp_CS_MemAbsSet.Set_BsRt_PowerGauge_Element
        OIE_pp_CS_MemAbsSet_MemAbstractMdl_Set_BsRt_RealTimeClock_ElementTrigBySet_BsRt_RealTimeClock_Element: start-on-event=MemAbstractMdl_Set_BsRt_RealTimeClock_Element, operation=pp_CS_MemAbsSet.Set_BsRt_RealTimeClock_Element
        OIE_pp_CS_MemAbsSet_MemAbstractMdl_Set_BsRt_SpeedoGauge_ElementTrigBySet_BsRt_SpeedoGauge_Element: start-on-event=MemAbstractMdl_Set_BsRt_SpeedoGauge_Element, operation=pp_CS_MemAbsSet.Set_BsRt_SpeedoGauge_Element
        OIE_pp_CS_MemAbsSet_MemAbstractMdl_Set_BsRt_TachoGauge_ElementTrigBySet_BsRt_TachoGauge_Element: start-on-event=MemAbstractMdl_Set_BsRt_TachoGauge_Element, operation=pp_CS_MemAbsSet.Set_BsRt_TachoGauge_Element
        OIE_pp_CS_MemAbsSet_MemAbstractMdl_Set_BsRt_TempGauge_ElementTrigBySet_BsRt_TempGauge_Element: start-on-event=MemAbstractMdl_Set_BsRt_TempGauge_Element, operation=pp_CS_MemAbsSet.Set_BsRt_TempGauge_Element
        OIE_pp_CS_MemAbsSet_MemAbstractMdl_Set_BsRt_TripComputer_ElementTrigBySet_BsRt_TripComputer_Element: start-on-event=MemAbstractMdl_Set_BsRt_TripComputer_Element, operation=pp_CS_MemAbsSet.Set_BsRt_TripComputer_Element
        OIE_pp_CS_MemAbsSet_MemAbstractMdl_Set_BsRt_Warning_ElementTrigBySet_BsRt_Warning_Element: start-on-event=MemAbstractMdl_Set_BsRt_Warning_Element, operation=pp_CS_MemAbsSet.Set_BsRt_Warning_Element
        OIE_pp_CS_MemAbsSet_MemAbstractMdl_Set_BsShare_EcuPartNumber_ElementTrigBySet_BsShare_EcuPartNumber_Element: start-on-event=MemAbstractMdl_Set_BsShare_EcuPartNumber_Element, operation=pp_CS_MemAbsSet.Set_BsShare_EcuPartNumber_Element
        OIE_pp_CS_MemAbsSet_MemAbstractMdl_Set_BsShare_SwUpdFotaFinPrint_ElementTrigBySet_BsShare_SwUpdFotaFinPrint_Element: start-on-event=MemAbstractMdl_Set_BsShare_SwUpdFotaFinPrint_Element, operation=pp_CS_MemAbsSet.Set_BsShare_SwUpdFotaFinPrint_Element
        OIE_pp_CS_MemAbsSet_MemAbstractMdl_Set_BsShare_SwUpdFotaMode_ElementTrigBySet_BsShare_SwUpdFotaMode_Element: start-on-event=MemAbstractMdl_Set_BsShare_SwUpdFotaMode_Element, operation=pp_CS_MemAbsSet.Set_BsShare_SwUpdFotaMode_Element
        OIE_pp_CS_MemAbsSet_MemAbstractMdl_Set_BsShare_SwUpdFotaStatus_ElementTrigBySet_BsShare_SwUpdFotaStatus_Element: start-on-event=MemAbstractMdl_Set_BsShare_SwUpdFotaStatus_Element, operation=pp_CS_MemAbsSet.Set_BsShare_SwUpdFotaStatus_Element
        OIE_pp_CS_MemAbsSet_MemAbstractMdl_Set_BsShare_SwUpdFotadecrypt_ElementTrigBySet_BsShare_SwUpdFotadecrypt_Element: start-on-event=MemAbstractMdl_Set_BsShare_SwUpdFotadecrypt_Element, operation=pp_CS_MemAbsSet.Set_BsShare_SwUpdFotadecrypt_Element
        OIE_pp_CS_MemAbsSet_MemAbstractMdl_Set_BsShare_SwUpdReflash_ElementTrigBySet_BsShare_SwUpdReflash_Element: start-on-event=MemAbstractMdl_Set_BsShare_SwUpdReflash_Element, operation=pp_CS_MemAbsSet.Set_BsShare_SwUpdReflash_Element
        OIE_pp_CS_MemAbsSet_MemAbstractMdl_Set_BsShare_VehicleConfig_ElementTrigBySet_BsShare_VehicleConfig_Element: start-on-event=MemAbstractMdl_Set_BsShare_VehicleConfig_Element, operation=pp_CS_MemAbsSet.Set_BsShare_VehicleConfig_Element
        OIE_pp_CS_MemAbsSet_MemAbstractMdl_Set_BsShare_VisMeet_ElementTrigBySet_BsShare_VisMeet_Element: start-on-event=MemAbstractMdl_Set_BsShare_VisMeet_Element, operation=pp_CS_MemAbsSet.Set_BsShare_VisMeet_Element
        OIE_pp_CS_MemAbsSet_MemAbstractMdl_Set_RefCys_Certicificate1_ElementTrigBySet_RefCys_Certicificate1_Element: start-on-event=MemAbstractMdl_Set_RefCys_Certicificate1_Element, operation=pp_CS_MemAbsSet.Set_RefCys_Certicificate1_Element
        OIE_pp_CS_MemAbsSet_MemAbstractMdl_Set_RefCys_Certicificate_ElementTrigBySet_RefCys_Certicificate_Element: start-on-event=MemAbstractMdl_Set_RefCys_Certicificate_Element, operation=pp_CS_MemAbsSet.Set_RefCys_Certicificate_Element
      timing event TEMemAbstractMdl_MainFunction: start-on-event=MemAbstractMdl_MainFunction, period=0.01
      port-api-options:
        enable-take-address=false, indirect-api=false, port=pp_CS_MemAbsGet
        enable-take-address=false, indirect-api=false, port=pp_CS_MemAbsSet
        enable-take-address=false, indirect-api=false, port=pp_CS_MemAbs_NvMWriteStatus
        enable-take-address=false, indirect-api=false, port=pp_SR_JobStatus
      122 x runnable, all with can-be-invoked-concurrently=true:
        MemAbstractMdl_NvmWriteStatus
        MemAbstractMdl_Get_BsConst_Audio_Element
        MemAbstractMdl_Get_BsConst_Communication_Element
        MemAbstractMdl_Get_BsConst_EngOffTimer_Element
        MemAbstractMdl_Get_BsConst_FuelGauge_Element
        MemAbstractMdl_Get_BsConst_Illumination_Element
        MemAbstractMdl_Get_BsConst_OilGauge_Element
        MemAbstractMdl_Get_BsConst_PowerGauge_Element
        MemAbstractMdl_Get_BsConst_Power_Element
        MemAbstractMdl_Get_BsConst_RealTimeClock_Element
        MemAbstractMdl_Get_BsConst_ServiceReminder_Element
        MemAbstractMdl_Get_BsConst_SpeedoGauge_Element
        MemAbstractMdl_Get_BsConst_TachoGauge_Element
        MemAbstractMdl_Get_BsConst_TempGauge_Element
        MemAbstractMdl_Get_BsConst_TripComputer_Element
        MemAbstractMdl_Get_BsConst_Warning_Element
        MemAbstractMdl_Get_BsCys_Certicificate_Element
        MemAbstractMdl_Get_BsDiag_Dtc_Element
        MemAbstractMdl_Get_BsDiag_ErrorRecord_Element
        MemAbstractMdl_Get_BsFuSa_Audio_Element
        MemAbstractMdl_Get_BsFuSa_Communication_Element
        MemAbstractMdl_Get_BsFuSa_Config_Element
        MemAbstractMdl_Get_BsFuSa_Display_Element
        MemAbstractMdl_Get_BsFuSa_Power_Element
        MemAbstractMdl_Get_BsFuSa_Warning_Element
        MemAbstractMdl_Get_BsFusa_Fota_Element
        MemAbstractMdl_Get_BsReten_Audio_Element
        MemAbstractMdl_Get_BsReten_Communication_Element
        MemAbstractMdl_Get_BsReten_Display_Element
        MemAbstractMdl_Get_BsReten_Gauges_Element
        MemAbstractMdl_Get_BsReten_Illumination_Element
        MemAbstractMdl_Get_BsReten_Odometer_Element
        MemAbstractMdl_Get_BsReten_Personalization_Element
        MemAbstractMdl_Get_BsReten_Power_Element
        MemAbstractMdl_Get_BsReten_RealTimeClock_Element
        MemAbstractMdl_Get_BsReten_Tripcomputer_Element
        MemAbstractMdl_Get_BsReten_VisDlt_Element
        MemAbstractMdl_Get_BsReten_Warning_Element
        MemAbstractMdl_Get_BsRt_CusDlt_Element
        MemAbstractMdl_Get_BsRt_FuelGauge_Element
        MemAbstractMdl_Get_BsRt_Illumination_Element
        MemAbstractMdl_Get_BsRt_Odometer_Element
        MemAbstractMdl_Get_BsRt_OilGauge_Element
        MemAbstractMdl_Get_BsRt_Personalization_Element
        MemAbstractMdl_Get_BsRt_PowerGauge_Element
        MemAbstractMdl_Get_BsRt_RealTimeClock_Element
        MemAbstractMdl_Get_BsRt_SpeedoGauge_Element
        MemAbstractMdl_Get_BsRt_TachoGauge_Element
        MemAbstractMdl_Get_BsRt_TempGauge_Element
        MemAbstractMdl_Get_BsRt_TripComputer_Element
        MemAbstractMdl_Get_BsRt_Warning_Element
        MemAbstractMdl_Get_BsShare_EcuPartNumber_Element
        MemAbstractMdl_Get_BsShare_SwUpdFotaFinPrint_Element
        MemAbstractMdl_Get_BsShare_SwUpdFotaMode_Element
        MemAbstractMdl_Get_BsShare_SwUpdFotaStatus_Element
        MemAbstractMdl_Get_BsShare_SwUpdFotadecrypt_Element
        MemAbstractMdl_Get_BsShare_SwUpdReflash_Element
        MemAbstractMdl_Get_BsShare_VehicleConfig_Element
        MemAbstractMdl_Get_BsShare_VisMeet_Element
        MemAbstractMdl_Get_RefCys_Certicificate1_Element
        MemAbstractMdl_Get_RefCys_Certicificate_Element
        MemAbstractMdl_Set_BsConst_Audio_Element
        MemAbstractMdl_Set_BsConst_Communication_Element
        MemAbstractMdl_Set_BsConst_EngOffTimer_Element
        MemAbstractMdl_Set_BsConst_FuelGauge_Element
        MemAbstractMdl_Set_BsConst_Illumination_Element
        MemAbstractMdl_Set_BsConst_OilGauge_Element
        MemAbstractMdl_Set_BsConst_PowerGauge_Element
        MemAbstractMdl_Set_BsConst_Power_Element
        MemAbstractMdl_Set_BsConst_RealTimeClock_Element
        MemAbstractMdl_Set_BsConst_ServiceReminder_Element
        MemAbstractMdl_Set_BsConst_SpeedoGauge_Element
        MemAbstractMdl_Set_BsConst_TachoGauge_Element
        MemAbstractMdl_Set_BsConst_TempGauge_Element
        MemAbstractMdl_Set_BsConst_TripComputer_Element
        MemAbstractMdl_Set_BsConst_Warning_Element
        MemAbstractMdl_Set_BsCys_Certicificate_Element
        MemAbstractMdl_Set_BsDiag_Dtc_Element
        MemAbstractMdl_Set_BsDiag_ErrorRecord_Element
        MemAbstractMdl_Set_BsFuSa_Audio_Element
        MemAbstractMdl_Set_BsFuSa_Communication_Element
        MemAbstractMdl_Set_BsFuSa_Config_Element
        MemAbstractMdl_Set_BsFuSa_Display_Element
        MemAbstractMdl_Set_BsFuSa_Power_Element
        MemAbstractMdl_Set_BsFuSa_Warning_Element
        MemAbstractMdl_Set_BsFusa_Fota_Element
        MemAbstractMdl_Set_BsReten_Audio_Element
        MemAbstractMdl_Set_BsReten_Communication_Element
        MemAbstractMdl_Set_BsReten_Display_Element
        MemAbstractMdl_Set_BsReten_Gauges_Element
        MemAbstractMdl_Set_BsReten_Illumination_Element
        MemAbstractMdl_Set_BsReten_Odometer_Element
        MemAbstractMdl_Set_BsReten_Personalization_Element
        MemAbstractMdl_Set_BsReten_Power_Element
        MemAbstractMdl_Set_BsReten_RealTimeClock_Element
        MemAbstractMdl_Set_BsReten_Tripcomputer_Element
        MemAbstractMdl_Set_BsReten_VisDlt_Element
        MemAbstractMdl_Set_BsReten_Warning_Element
        MemAbstractMdl_Set_BsRt_CusDlt_Element
        MemAbstractMdl_Set_BsRt_FuelGauge_Element
        MemAbstractMdl_Set_BsRt_Illumination_Element
        MemAbstractMdl_Set_BsRt_Odometer_Element
        MemAbstractMdl_Set_BsRt_OilGauge_Element
        MemAbstractMdl_Set_BsRt_Personalization_Element
        MemAbstractMdl_Set_BsRt_PowerGauge_Element
        MemAbstractMdl_Set_BsRt_RealTimeClock_Element
        MemAbstractMdl_Set_BsRt_SpeedoGauge_Element
        MemAbstractMdl_Set_BsRt_TachoGauge_Element
        MemAbstractMdl_Set_BsRt_TempGauge_Element
        MemAbstractMdl_Set_BsRt_TripComputer_Element
        MemAbstractMdl_Set_BsRt_Warning_Element
        MemAbstractMdl_Set_BsShare_EcuPartNumber_Element
        MemAbstractMdl_Set_BsShare_SwUpdFotaFinPrint_Element
        MemAbstractMdl_Set_BsShare_SwUpdFotaMode_Element
        MemAbstractMdl_Set_BsShare_SwUpdFotaStatus_Element
        MemAbstractMdl_Set_BsShare_SwUpdFotadecrypt_Element
        MemAbstractMdl_Set_BsShare_SwUpdReflash_Element
        MemAbstractMdl_Set_BsShare_VehicleConfig_Element
        MemAbstractMdl_Set_BsShare_VisMeet_Element
        MemAbstractMdl_Set_RefCys_Certicificate1_Element
        MemAbstractMdl_Set_RefCys_Certicificate_Element
        MemAbstractMdl_MainFunction
          data-send-points:
            60 x access:
              DWA_pp_SR_JobStatus_JobStatus_BsConst_Audio_Element: accessed-variable=pp_SR_JobStatus.JobStatus_BsConst_Audio_Element
              DWA_pp_SR_JobStatus_JobStatus_BsConst_Communication_Element: accessed-variable=pp_SR_JobStatus.JobStatus_BsConst_Communication_Element
              DWA_pp_SR_JobStatus_JobStatus_BsConst_EngOffTimer_Element: accessed-variable=pp_SR_JobStatus.JobStatus_BsConst_EngOffTimer_Element
              DWA_pp_SR_JobStatus_JobStatus_BsConst_FuelGauge_Element: accessed-variable=pp_SR_JobStatus.JobStatus_BsConst_FuelGauge_Element
              DWA_pp_SR_JobStatus_JobStatus_BsConst_Illumination_Element: accessed-variable=pp_SR_JobStatus.JobStatus_BsConst_Illumination_Element
              DWA_pp_SR_JobStatus_JobStatus_BsConst_OilGauge_Element: accessed-variable=pp_SR_JobStatus.JobStatus_BsConst_OilGauge_Element
              DWA_pp_SR_JobStatus_JobStatus_BsConst_PowerGauge_Element: accessed-variable=pp_SR_JobStatus.JobStatus_BsConst_PowerGauge_Element
              DWA_pp_SR_JobStatus_JobStatus_BsConst_Power_Element: accessed-variable=pp_SR_JobStatus.JobStatus_BsConst_Power_Element
              DWA_pp_SR_JobStatus_JobStatus_BsConst_RealTimeClock_Element: accessed-variable=pp_SR_JobStatus.JobStatus_BsConst_RealTimeClock_Element
              DWA_pp_SR_JobStatus_JobStatus_BsConst_ServiceReminder_Element: accessed-variable=pp_SR_JobStatus.JobStatus_BsConst_ServiceReminder_Element
              DWA_pp_SR_JobStatus_JobStatus_BsConst_SpeedoGauge_Element: accessed-variable=pp_SR_JobStatus.JobStatus_BsConst_SpeedoGauge_Element
              DWA_pp_SR_JobStatus_JobStatus_BsConst_TachoGauge_Element: accessed-variable=pp_SR_JobStatus.JobStatus_BsConst_TachoGauge_Element
              DWA_pp_SR_JobStatus_JobStatus_BsConst_TempGauge_Element: accessed-variable=pp_SR_JobStatus.JobStatus_BsConst_TempGauge_Element
              DWA_pp_SR_JobStatus_JobStatus_BsConst_TripComputer_Element: accessed-variable=pp_SR_JobStatus.JobStatus_BsConst_TripComputer_Element
              DWA_pp_SR_JobStatus_JobStatus_BsConst_Warning_Element: accessed-variable=pp_SR_JobStatus.JobStatus_BsConst_Warning_Element
              DWA_pp_SR_JobStatus_JobStatus_BsCys_Certicificate_Element: accessed-variable=pp_SR_JobStatus.JobStatus_BsCys_Certicificate_Element
              DWA_pp_SR_JobStatus_JobStatus_BsDiag_Dtc_Element: accessed-variable=pp_SR_JobStatus.JobStatus_BsDiag_Dtc_Element
              DWA_pp_SR_JobStatus_JobStatus_BsDiag_ErrorRecord_Element: accessed-variable=pp_SR_JobStatus.JobStatus_BsDiag_ErrorRecord_Element
              DWA_pp_SR_JobStatus_JobStatus_BsFuSa_Audio_Element: accessed-variable=pp_SR_JobStatus.JobStatus_BsFuSa_Audio_Element
              DWA_pp_SR_JobStatus_JobStatus_BsFuSa_Communication_Element: accessed-variable=pp_SR_JobStatus.JobStatus_BsFuSa_Communication_Element
              DWA_pp_SR_JobStatus_JobStatus_BsFuSa_Config_Element: accessed-variable=pp_SR_JobStatus.JobStatus_BsFuSa_Config_Element
              DWA_pp_SR_JobStatus_JobStatus_BsFuSa_Display_Element: accessed-variable=pp_SR_JobStatus.JobStatus_BsFuSa_Display_Element
              DWA_pp_SR_JobStatus_JobStatus_BsFuSa_Power_Element: accessed-variable=pp_SR_JobStatus.JobStatus_BsFuSa_Power_Element
              DWA_pp_SR_JobStatus_JobStatus_BsFuSa_Warning_Element: accessed-variable=pp_SR_JobStatus.JobStatus_BsFuSa_Warning_Element
              DWA_pp_SR_JobStatus_JobStatus_BsFusa_Fota_Element: accessed-variable=pp_SR_JobStatus.JobStatus_BsFusa_Fota_Element
              DWA_pp_SR_JobStatus_JobStatus_BsReten_Audio_Element: accessed-variable=pp_SR_JobStatus.JobStatus_BsReten_Audio_Element
              DWA_pp_SR_JobStatus_JobStatus_BsReten_Communication_Element: accessed-variable=pp_SR_JobStatus.JobStatus_BsReten_Communication_Element
              DWA_pp_SR_JobStatus_JobStatus_BsReten_Display_Element: accessed-variable=pp_SR_JobStatus.JobStatus_BsReten_Display_Element
              DWA_pp_SR_JobStatus_JobStatus_BsReten_Gauges_Element: accessed-variable=pp_SR_JobStatus.JobStatus_BsReten_Gauges_Element
              DWA_pp_SR_JobStatus_JobStatus_BsReten_Illumination_Element: accessed-variable=pp_SR_JobStatus.JobStatus_BsReten_Illumination_Element
              DWA_pp_SR_JobStatus_JobStatus_BsReten_Odometer_Element: accessed-variable=pp_SR_JobStatus.JobStatus_BsReten_Odometer_Element
              DWA_pp_SR_JobStatus_JobStatus_BsReten_Personalization_Element: accessed-variable=pp_SR_JobStatus.JobStatus_BsReten_Personalization_Element
              DWA_pp_SR_JobStatus_JobStatus_BsReten_Power_Element: accessed-variable=pp_SR_JobStatus.JobStatus_BsReten_Power_Element
              DWA_pp_SR_JobStatus_JobStatus_BsReten_RealTimeClock_Element: accessed-variable=pp_SR_JobStatus.JobStatus_BsReten_RealTimeClock_Element
              DWA_pp_SR_JobStatus_JobStatus_BsReten_Tripcomputer_Element: accessed-variable=pp_SR_JobStatus.JobStatus_BsReten_Tripcomputer_Element
              DWA_pp_SR_JobStatus_JobStatus_BsReten_VisDlt_Element: accessed-variable=pp_SR_JobStatus.JobStatus_BsReten_VisDlt_Element
              DWA_pp_SR_JobStatus_JobStatus_BsReten_Warning_Element: accessed-variable=pp_SR_JobStatus.JobStatus_BsReten_Warning_Element
              DWA_pp_SR_JobStatus_JobStatus_BsRt_CusDlt_Element: accessed-variable=pp_SR_JobStatus.JobStatus_BsRt_CusDlt_Element
              DWA_pp_SR_JobStatus_JobStatus_BsRt_FuelGauge_Element: accessed-variable=pp_SR_JobStatus.JobStatus_BsRt_FuelGauge_Element
              DWA_pp_SR_JobStatus_JobStatus_BsRt_Illumination_Element: accessed-variable=pp_SR_JobStatus.JobStatus_BsRt_Illumination_Element
              DWA_pp_SR_JobStatus_JobStatus_BsRt_Odometer_Element: accessed-variable=pp_SR_JobStatus.JobStatus_BsRt_Odometer_Element
              DWA_pp_SR_JobStatus_JobStatus_BsRt_OilGauge_Element: accessed-variable=pp_SR_JobStatus.JobStatus_BsRt_OilGauge_Element
              DWA_pp_SR_JobStatus_JobStatus_BsRt_Personalization_Element: accessed-variable=pp_SR_JobStatus.JobStatus_BsRt_Personalization_Element
              DWA_pp_SR_JobStatus_JobStatus_BsRt_PowerGauge_Element: accessed-variable=pp_SR_JobStatus.JobStatus_BsRt_PowerGauge_Element
              DWA_pp_SR_JobStatus_JobStatus_BsRt_RealTimeClock_Element: accessed-variable=pp_SR_JobStatus.JobStatus_BsRt_RealTimeClock_Element
              DWA_pp_SR_JobStatus_JobStatus_BsRt_SpeedoGauge_Element: accessed-variable=pp_SR_JobStatus.JobStatus_BsRt_SpeedoGauge_Element
              DWA_pp_SR_JobStatus_JobStatus_BsRt_TachoGauge_Element: accessed-variable=pp_SR_JobStatus.JobStatus_BsRt_TachoGauge_Element
              DWA_pp_SR_JobStatus_JobStatus_BsRt_TempGauge_Element: accessed-variable=pp_SR_JobStatus.JobStatus_BsRt_TempGauge_Element
              DWA_pp_SR_JobStatus_JobStatus_BsRt_TripComputer_Element: accessed-variable=pp_SR_JobStatus.JobStatus_BsRt_TripComputer_Element
              DWA_pp_SR_JobStatus_JobStatus_BsRt_Warning_Element: accessed-variable=pp_SR_JobStatus.JobStatus_BsRt_Warning_Element
              DWA_pp_SR_JobStatus_JobStatus_BsShare_EcuPartNumber_Element: accessed-variable=pp_SR_JobStatus.JobStatus_BsShare_EcuPartNumber_Element
              DWA_pp_SR_JobStatus_JobStatus_BsShare_SwUpdFotaFinPrint_Element: accessed-variable=pp_SR_JobStatus.JobStatus_BsShare_SwUpdFotaFinPrint_Element
              DWA_pp_SR_JobStatus_JobStatus_BsShare_SwUpdFotaMode_Element: accessed-variable=pp_SR_JobStatus.JobStatus_BsShare_SwUpdFotaMode_Element
              DWA_pp_SR_JobStatus_JobStatus_BsShare_SwUpdFotaStatus_Element: accessed-variable=pp_SR_JobStatus.JobStatus_BsShare_SwUpdFotaStatus_Element
              DWA_pp_SR_JobStatus_JobStatus_BsShare_SwUpdFotadecrypt_Element: accessed-variable=pp_SR_JobStatus.JobStatus_BsShare_SwUpdFotadecrypt_Element
              DWA_pp_SR_JobStatus_JobStatus_BsShare_SwUpdReflash_Element: accessed-variable=pp_SR_JobStatus.JobStatus_BsShare_SwUpdReflash_Element
              DWA_pp_SR_JobStatus_JobStatus_BsShare_VehicleConfig_Element: accessed-variable=pp_SR_JobStatus.JobStatus_BsShare_VehicleConfig_Element
              DWA_pp_SR_JobStatus_JobStatus_BsShare_VisMeet_Element: accessed-variable=pp_SR_JobStatus.JobStatus_BsShare_VisMeet_Element
              DWA_pp_SR_JobStatus_JobStatus_RefCys_Certicificate1_Element: accessed-variable=pp_SR_JobStatus.JobStatus_RefCys_Certicificate1_Element
              DWA_pp_SR_JobStatus_JobStatus_RefCys_Certicificate_Element: accessed-variable=pp_SR_JobStatus.JobStatus_RefCys_Certicificate_Element
  swc implementation IMPL_MemAbstractMdl: behavior=IB_MemAbstractMdl
